# APP_DCC register map
Vendor: Texas Instruments
Peripheral module from a debugger description file (folder xwrl64xx).
Registers are 32-bit, access per field, no defined reset value unless marked. A register's access mark holds for its fields unless they carry their own. Offsets are as the file gives them; lines under a group give offsets from that group; [hi:lo] are bit positions; {n}, {i} and the like mark numbered series; 'fields as' and 'values as' point back to an identical list; <NAME> marks a mode.

## APP_DCC
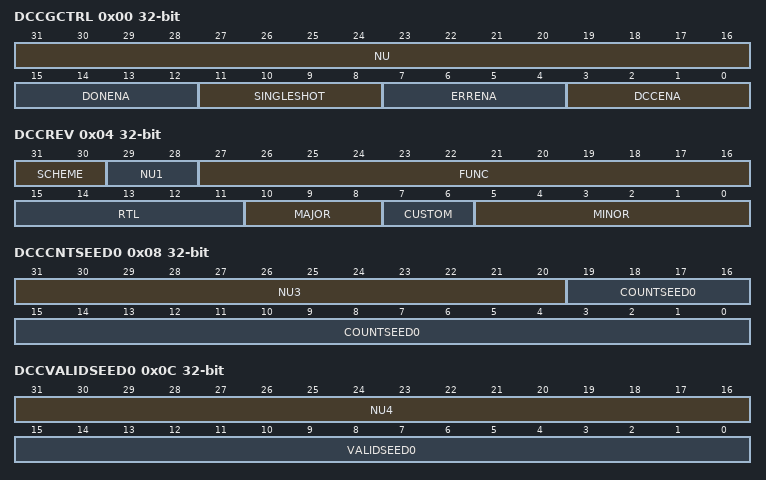
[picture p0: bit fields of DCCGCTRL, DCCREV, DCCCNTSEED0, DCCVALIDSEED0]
0x00 DCCGCTRL — Starts / stops the counters clears the error signal
  [31:16] NU ro — Reserved
  [15:12] DONENA rw — The DONEENA bit enables/disables the done signal. 0101 = disabled & 1010 = enabled
  [11:8] SINGLESHOT rw — Single/Continuous checking mode. 0101 = Continuous & 1010 = Single
  [7:4] ERRENA rw — The ERRENA bit enables/disables the error signal. 0101 = disabled & 1010 = enabled
  [3:0] DCCENA rw — The DCCENA bit starts and stops the operation of the dcc 0101 = disabled & 1010 = enabled
0x04 DCCREV ro — Module version
  [31:30] SCHEME — SCHEME. - (RO )
  [29:28] NU1 — Reserved
  [27:16] FUNC — Functional release number - (RO )
  [15:11] RTL — Design Release Number - (RO )
  [10:8] MAJOR — Major Revision Number - (RO )
  [7:6] CUSTOM — Indicates a special version of the module. May not be supported by standard software - (RO )
  [5:0] MINOR — Minor revision number. - (RO )
0x08 DCCCNTSEED0 — Seed value for the counter attached to clock source 0
  [31:20] NU3 ro — Reserved
  [19:0] COUNTSEED0 rw — The seed value for Counter 0. The seed value that gets loaded into counter 0 (clock source 0)
0x0C DCCVALIDSEED0 — Seed value for the timeout counter attached to clock source 0
  [31:16] NU4 ro — Reserved
  [15:0] VALIDSEED0 rw — The seed value for Valid Duration Counter 0.The seed value that gets loaded into the valid duration counter for clock source 0
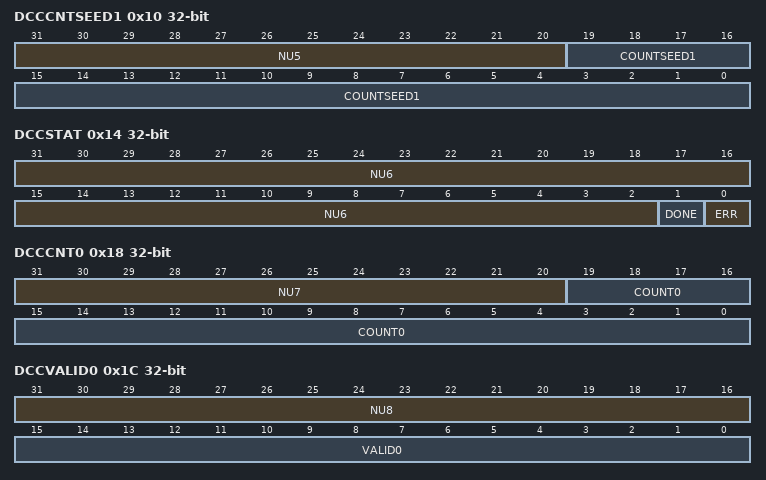
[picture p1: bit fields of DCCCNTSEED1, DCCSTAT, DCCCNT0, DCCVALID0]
0x10 DCCCNTSEED1 — Seed value for the counter attached to clock source 1
  [31:20] NU5 ro — Reserved
  [19:0] COUNTSEED1 rw — The seed value for Counter 1. The seed value that gets loaded into counter 1 (clock source 1
0x14 DCCSTAT — Contains the error & done flag bit
  [31:2] NU6 ro — Reserved
  [1] DONE rw — Indicates whether or not an done has occured. Writing a 1 to this bit clears the flag.
  [0] ERR rw — Indicates whether or not an error has occured. Writing a 1 to this bit clears the flag.
0x18 DCCCNT0 ro — Value of the counter attached to clock source 0
  [31:20] NU7 — Reserved
  [19:0] COUNT0 — This field contains the current value of counter 0. - (RO )
0x1C DCCVALID0 ro — Value of the valid counter attached to clock source 0
  [31:16] NU8 — Reserved
  [15:0] VALID0 — This field contains the current value of valid counter 0. - (RO )
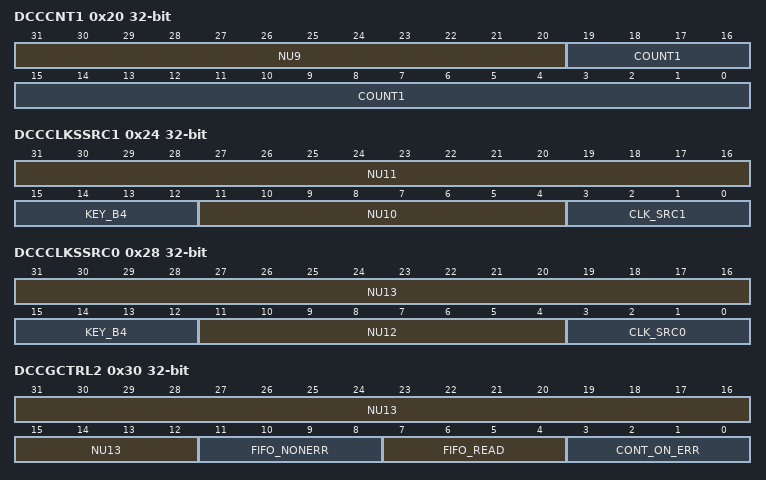
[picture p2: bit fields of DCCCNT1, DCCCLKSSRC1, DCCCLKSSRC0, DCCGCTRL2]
0x20 DCCCNT1 ro — Value of the counter attached to clock source 1
  [31:20] NU9 — Reserved
  [19:0] COUNT1 — This field contains the current value of counter 1. - (RO )
0x24 DCCCLKSSRC1 — Clock source1 selection control
  [31:16] NU11 ro — Reserved
  [15:12] KEY_B4 rw — Key Programing (1010 is the KEY Value)
  [11:4] NU10 ro — Reserved
  [3:0] CLK_SRC1 rw — RCOSC Input1_clksrc[10] CANFD_GCM Input1_clksrc[9] APPSS_GCM Input1_clksrc[8] OSC_CLK Input1_clksrc[7] LIN_CLK Input1_clksrc[6] MDLL_CLK Input1_clksrc[5] SYNTH_CLK Input1_clksrc[4] RAMPGEN/DFE CLK Input1_clksrc[3] GPADC CLK Input1_clksrc[2] FECSS_GCM Input1_clksrc[1] fast_clk(muxed apll and pll_dig_clk )(root mux) Input1_clksrc[0]
0x28 DCCCLKSSRC0 — Clock source0 selection control
  [31:16] NU13 ro — Reserved
  [15:12] KEY_B4 rw — Key Programing (1010 is the KEY Value)
  [11:4] NU12 ro — Reserved
  [3:0] CLK_SRC0 rw — APLL clock 400MHz Input0_clksrc[2] PLL_DIG clock 400MHz Input0_clksrc[1] OSC_CLK Input0_clksrc[0]
0x30 DCCGCTRL2 — Global control register 2
  [31:12] NU13 ro
  [11:8] FIFO_NONERR rw — FIFO update on Non-Error Enables/disables FIFO writes without the error event on completion of comparison window. 0101: Counter values are captured to non-full FIFO only upon Error event Others: Write counter values to non-full FIFO upon completion of comparison window regardless of error or not. Note this setting is applicable only in Continuous mode; in single shot mode FIFO captures counts only on Error. Note: The user should write 1010 to these enable fields to enable each feature to avoid single soft errors.
  [7:4] FIFO_READ rw — FIFO Read Enable Enables the counter read registers reflect FIFO output instead of live counter value. 0101: Counter value is read directly. Others: FIFO output is read Note: The user should write 1010 to these enable fields to enable each feature to avoid single soft errors.
  [3:0] CONT_ON_ERR rw — Continue on Error enable Continues to next window of comparison despite the error condition. 0101: Comparison and counter reload is stopped from advancing if error is detected. Others: Counters get reloaded with seed and continue counting despite the error condition. Note: The user should write 1010 to these enable fields to enable each feature to avoid single soft errors.
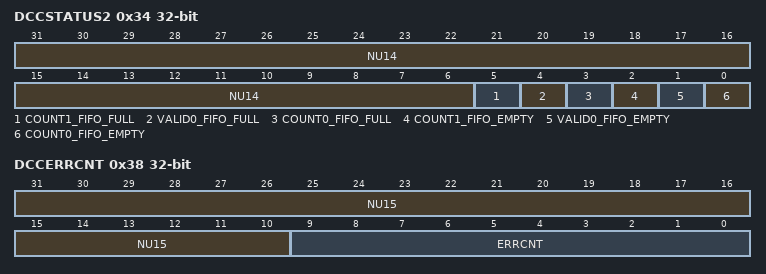
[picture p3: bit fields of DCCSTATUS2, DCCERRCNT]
0x34 DCCSTATUS2 ro — FIFO status register
  [31:6] NU14 — Reserved
  [5] COUNT1_FIFO_FULL — Count1 FIFO Full Indicates whether Count1 FIFO is Full. 0: Count1 FIFO is not Full 1: Count1 FIFO is Full.
  [4] VALID0_FIFO_FULL — Valid0 FIFO Full Indicates whether Valid0 FIFO is Full. 0: Valid0 FIFO is not Full 1: Valid0 FIFO is Full.
  [3] COUNT0_FIFO_FULL — Count0 FIFO Full Indicates whether Count0 FIFO is Full. 0: Count0 FIFO is not Full 1: Count0 FIFO is Full.
  [2] COUNT1_FIFO_EMPTY — Count1 FIFO Empty Indicates whether Count1 FIFO is Empty. 0: Count1 FIFO is not empty 1: Count1 FIFO is empty.
  [1] VALID0_FIFO_EMPTY — Valid0 FIFO Empty Indicates whether Valid0 FIFO is Empty. 0: Valid0 FIFO is not empty 1: Valid0 FIFO is empty.
  [0] COUNT0_FIFO_EMPTY — Count0 FIFO Empty Indicates whether Count0 FIFO is Empty. 0: Count0 FIFO is not empty 1: Count0 FIFO is empty.
0x38 DCCERRCNT — Error count register
  [31:10] NU15 ro — Reserved
  [9:0] ERRCNT rw — Counts the number of errors after the last write to this register or reset. If reached terminal count the count freezes. User needs to clear it.
